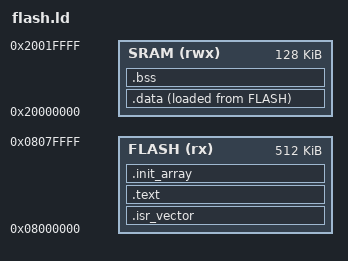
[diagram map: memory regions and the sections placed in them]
ENTRY(Reset_Handler)

/* Memory layout for typical Cortex-M4 (e.g., STM32F401: 512K Flash, 96K RAM) */
MEMORY
{
    FLASH (rx)  : ORIGIN = 0x08000000, LENGTH = 512K
    SRAM  (rwx) : ORIGIN = 0x20000000, LENGTH = 128K
}

_estack = ORIGIN(SRAM) + LENGTH(SRAM); /* Top of Main Stack Pointer */

SECTIONS
{
    /* Vector Table placed at base of executable Flash */
    .isr_vector :
    {
        . = ALIGN(4);
        KEEP(*(.isr_vector))
        . = ALIGN(4);
    } > FLASH

    /* Program code and constants */
    .text :
    {
        . = ALIGN(4);
        *(.text)
        *(.text*)
        *(.rodata)
        *(.rodata*)
        . = ALIGN(4);
        _etext = .;
    } > FLASH

    /* Static initialization arrays for global C++ constructors */
    .init_array :
    {
        . = ALIGN(4);
        PROVIDE_HIDDEN(__init_array_start = .);
        KEEP(*(SORT(.init_array.*)))
        KEEP(*(.init_array*))
        PROVIDE_HIDDEN(__init_array_end = .);
        . = ALIGN(4);
    } > FLASH

    /* Load Address of initialized variables stored in Flash */
    _sidata = LOADADDR(.data);

    /* Initialized data residing in SRAM */
    .data :
    {
        . = ALIGN(4);
        _sdata = .;
        *(.data)
        *(.data*)
        . = ALIGN(4);
        _edata = .;
    } > SRAM AT > FLASH

    /* Uninitialized variables zeroed at startup */
    .bss :
    {
        . = ALIGN(4);
        _sbss = .;
        __bss_start__ = _sbss;
        *(.bss)
        *(.bss*)
        *(COMMON)
        . = ALIGN(4);
        _ebss = .;
        __bss_end__ = _ebss;
    } > SRAM

    /* Discard exception frame unwind indices */
    /DISCARD/ :
    {
        *(.ARM.exidx*)
        *(.ARM.extab*)
    }
}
